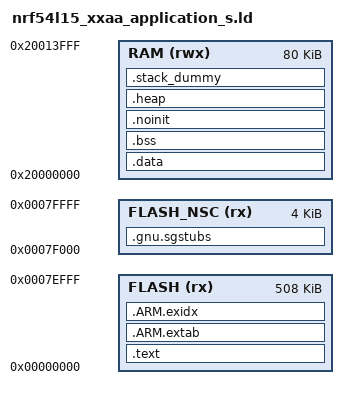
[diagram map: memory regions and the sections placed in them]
/* Linker script for the nRF54L15 secure application image. */

SEARCH_DIR(.)
GROUP(-lgcc -lc -lnosys)

MEMORY
{
  FLASH (rx)     : ORIGIN = 0x00000000, LENGTH = 0x0007F000
  FLASH_NSC (rx) : ORIGIN = 0x0007F000, LENGTH = 0x00001000
  RAM (rwx)      : ORIGIN = 0x20000000, LENGTH = 0x00014000
}

ENTRY(Reset_Handler)

SECTIONS
{
    .text :
    {
        KEEP(*(.isr_vector))
        *(.text*)

        KEEP(*(.init))
        KEEP(*(.fini))

        *crtbegin.o(.ctors)
        *crtbegin?.o(.ctors)
        *(EXCLUDE_FILE(*crtend?.o *crtend.o) .ctors)
        *(SORT(.ctors.*))
        *(.ctors)

        *crtbegin.o(.dtors)
        *crtbegin?.o(.dtors)
        *(EXCLUDE_FILE(*crtend?.o *crtend.o) .dtors)
        *(SORT(.dtors.*))
        *(.dtors)

        *(.rodata*)
        KEEP(*(.eh_frame*))
    } > FLASH

    .gnu.sgstubs :
    {
        . = ALIGN(32);
        __sg_start = .;
        KEEP(*(.gnu.sgstubs*))
    } > FLASH_NSC

    __sg_end = .;
    . = ALIGN(32);
    __nsc_size = . - __sg_start;

    .ARM.extab :
    {
        *(.ARM.extab* .gnu.linkonce.armextab.*)
    } > FLASH

    __exidx_start = .;
    .ARM.exidx :
    {
        *(.ARM.exidx* .gnu.linkonce.armexidx.*)
    } > FLASH
    __exidx_end = .;

    . = ALIGN(4);
    __etext = .;

    .data : AT (__etext)
    {
        __data_start__ = .;
        *(vtable)
        *(.data*)

        . = ALIGN(4);
        PROVIDE_HIDDEN (__preinit_array_start = .);
        KEEP(*(.preinit_array))
        PROVIDE_HIDDEN (__preinit_array_end = .);

        . = ALIGN(4);
        PROVIDE_HIDDEN (__init_array_start = .);
        KEEP(*(SORT(.init_array.*)))
        KEEP(*(.init_array))
        PROVIDE_HIDDEN (__init_array_end = .);

        . = ALIGN(4);
        PROVIDE_HIDDEN (__fini_array_start = .);
        KEEP(*(SORT(.fini_array.*)))
        KEEP(*(.fini_array))
        PROVIDE_HIDDEN (__fini_array_end = .);

        KEEP(*(.jcr*))
        . = ALIGN(4);
        __data_end__ = .;
    } > RAM

    .bss :
    {
        . = ALIGN(4);
        __bss_start__ = .;
        *(.bss*)
        *(COMMON)
        . = ALIGN(4);
        __bss_end__ = .;
    } > RAM

    .noinit (NOLOAD) :
    {
        . = ALIGN(4);
        KEEP(*(.noinit*))
        . = ALIGN(4);
    } > RAM

    .heap (COPY):
    {
        __HeapBase = .;
        __end__ = .;
        PROVIDE(end = .);
        KEEP(*(.heap*))
        __HeapLimit = .;
    } > RAM

    .stack_dummy (COPY):
    {
        KEEP(*(.stack*))
    } > RAM

    __StackTop = ORIGIN(RAM) + LENGTH(RAM);
    __StackLimit = __StackTop - SIZEOF(.stack_dummy);
    PROVIDE(__stack = __StackTop);

    ASSERT(__StackLimit >= __HeapLimit, "region RAM overflowed with stack")

    DataInitFlashUsed = __bss_start__ - __data_start__;
    CodeFlashUsed = __etext - ORIGIN(FLASH);
    TotalFlashUsed = CodeFlashUsed + DataInitFlashUsed;
    ASSERT(TotalFlashUsed <= LENGTH(FLASH), "region FLASH overflowed with .data and user data")
}
